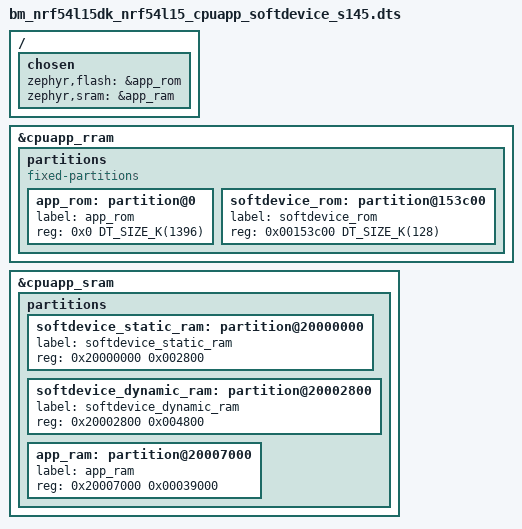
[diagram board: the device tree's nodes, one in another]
/*
 * Copyright (c) 2025 Nordic Semiconductor ASA
 *
 * SPDX-License-Identifier: LicenseRef-Nordic-5-Clause
 */

/dts-v1/;

#include <nordic/nrf54l15_cpuapp.dtsi>
#include "bm_nrf54l15dk_nrf54l15_cpuapp_common.dtsi"

/ {
	chosen {
		/delete-property/ zephyr,code-partition;
		zephyr,flash = &app_rom;
		zephyr,sram = &app_ram;
	};
};

&cpuapp_rram {
	status = "okay";

	partitions {
		compatible = "fixed-partitions";
		#address-cells = <1>;
		#size-cells = <1>;

        app_rom: partition@0 {
			label = "app_rom";
			reg = <0x0 DT_SIZE_K(1396)>;
		};

		softdevice_rom: partition@153c00 {
			label = "softdevice_rom";
			reg = <0x00153c00 DT_SIZE_K(128)>;
		};
	};
};

&cpuapp_sram {
	status = "okay";

	partitions {
		#address-cells = <1>;
		#size-cells = <1>;

        softdevice_static_ram: partition@20000000 {
            label = "softdevice_static_ram";
            reg = <0x20000000 0x002800>;
        };

        softdevice_dynamic_ram: partition@20002800 {
            label = "softdevice_dynamic_ram";
            reg = <0x20002800 0x004800>;
        };

        app_ram: partition@20007000 {
            label = "app_ram";
            reg = <0x20007000 0x00039000>;
        };
	};
};

